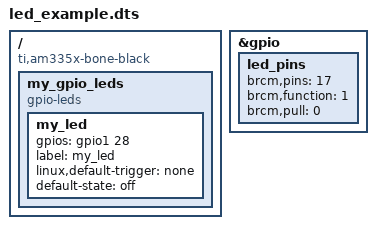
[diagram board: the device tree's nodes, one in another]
/*
 * led_example.dts - Device Tree Overlay for LED Control
 *
 * AUTO-GENERATED: This file was generated by AI. Verify before use.
 *
 * This overlay demonstrates how to add LED devices to the device tree.
 * It uses the Linux gpio-leds driver to expose LEDs via /sys/class/leds/
 *
 * Target: BeagleBone Black Rev. C (AM335x)
 * GPIO configuration uses the AM335x GPIO banks.
 *
 * Compilation:
 *   dtc -@ -I dts -O dtb -o led_example.dtbo led_example.dts
 *
 * Installation (BeagleBone Black):
 *   sudo cp led_example.dtbo /lib/firmware/
 *   # Load at runtime:
 *   echo led_example > /sys/devices/platform/bone_capemgr/slots
 *   # Or configure via uEnv.txt for boot-time loading
 *
 * Verification:
 *   ls /sys/class/leds/
 *   cat /sys/class/leds/my_led/trigger
 *   echo 1 > /sys/class/leds/my_led/brightness
 *   echo 0 > /sys/class/leds/my_led/brightness
 *
 * Hardware Connection (BeagleBone Black P9 Header):
 *   P9_12 (GPIO1_28 = GPIO 60) --> LED anode (+)
 *   P9_1 or P9_2 (GND)         --> LED cathode (-) through 330Ω resistor
 *
 * AM335x GPIO Numbering:
 *   GPIO bank 0: GPIO 0-31   (e.g., GPIO0_7 = GPIO 7)
 *   GPIO bank 1: GPIO 32-63  (e.g., GPIO1_28 = GPIO 60)
 *   GPIO bank 2: GPIO 64-95  (e.g., GPIO2_1 = GPIO 65)
 *   GPIO bank 3: GPIO 96-127 (e.g., GPIO3_19 = GPIO 115)
 */

/dts-v1/;
/plugin/;

/ {
    /*
     * Compatibility string for BeagleBone Black
     */
    compatible = "ti,am335x-bone-black", "ti,am335x-bone", "ti,am33xx";

    /*
     * Fragment 0: Add LED device to root node
     */
    fragment@0 {
        target-path = "/";
        __overlay__ {
            /*
             * GPIO LEDs container node
             * Uses the standard Linux gpio-leds driver
             */
            my_gpio_leds {
                compatible = "gpio-leds";
                
                /*
                 * LED 1: Simple status LED on GPIO1_28 (P9_12)
                 * GPIO number = (bank * 32) + offset = (1 * 32) + 28 = 60
                 */
                my_led: my_led {
                    /*
                     * GPIO specification for AM335x:
                     * <&gpioN OFFSET FLAGS>
                     * 
                     * BeagleBone Black has gpio0, gpio1, gpio2, gpio3
                     * 
                     * Flags:
                     *   GPIO_ACTIVE_HIGH = 0
                     *   GPIO_ACTIVE_LOW  = 1
                     */
                    gpios = <&gpio1 28 0>;  /* GPIO1_28 (P9_12), active high */
                    
                    /*
                     * Label appears in /sys/class/leds/<label>/
                     */
                    label = "my_led";
                    
                    /*
                     * Available triggers:
                     *   none       - Manual control only
                     *   heartbeat  - Kernel heartbeat pattern
                     *   timer      - Configurable on/off times
                     *   mmc0       - SD card activity
                     *   cpu0       - CPU activity
                     *   gpio       - Follows another GPIO
                     *   default-on - LED on by default
                     *
                     * List all: cat /sys/class/leds/my_led/trigger
                     */
                    linux,default-trigger = "none";
                    
                    /*
                     * Default state at boot:
                     *   0 = off
                     *   1 = on
                     */
                    default-state = "off";
                };
                
                /*
                 * LED 2: Heartbeat LED on GPIO1_17 (P9_23) - optional
                 * Uncomment to add second LED
                 */
                /*
                heartbeat_led: heartbeat_led {
                    gpios = <&gpio 27 0>;
                    label = "heartbeat";
                    linux,default-trigger = "heartbeat";
                    default-state = "on";
                };
                */
                
                /*
                 * LED 3: Activity LED on GPIO 22 (optional)
                 * Shows MMC/SD card activity
                 */
                /*
                activity_led: activity_led {
                    gpios = <&gpio 22 0>;
                    label = "activity";
                    linux,default-trigger = "mmc0";
                };
                */
            };
        };
    };

    /*
     * Fragment 1: Configure GPIO pin as output (optional)
     * Some platforms require explicit pinmux configuration
     */
    fragment@1 {
        target = <&gpio>;
        __overlay__ {
            /*
             * Pin configuration for LED GPIOs
             * Specific to Broadcom/Raspberry Pi pinctrl
             */
            led_pins: led_pins {
                brcm,pins = <17>;       /* GPIO numbers */
                brcm,function = <1>;    /* 1 = output */
                brcm,pull = <0>;        /* 0 = none, 1 = down, 2 = up */
            };
        };
    };

    /*
     * Parameters (Raspberry Pi specific)
     * Allows customization from config.txt:
     *   dtoverlay=led_example,gpio_pin=18
     */
    __overrides__ {
        gpio_pin = <&my_led>,"gpios:4";  /* Override GPIO number */
        /* Format: <&node>,"property:byte_offset" */
    };
};

/*
 * ===========================================================================
 * BeagleBone Black Version
 * ===========================================================================
 * Uncomment and use this version for BeagleBone Black
 *
 * /dts-v1/;
 * /plugin/;
 * 
 * / {
 *     compatible = "ti,am335x-bone-black";
 *     
 *     fragment@0 {
 *         target-path = "/";
 *         __overlay__ {
 *             bbb_leds {
 *                 compatible = "gpio-leds";
 *                 pinctrl-names = "default";
 *                 pinctrl-0 = <&bbb_led_pins>;
 *                 
 *                 bbb_led {
 *                     // GPIO1_28 = 32 + 28 = 60
 *                     gpios = <&gpio1 28 GPIO_ACTIVE_HIGH>;
 *                     label = "bbb_status";
 *                     linux,default-trigger = "heartbeat";
 *                 };
 *             };
 *         };
 *     };
 *     
 *     fragment@1 {
 *         target = <&am33xx_pinmux>;
 *         __overlay__ {
 *             bbb_led_pins: bbb_led_pins {
 *                 pinctrl-single,pins = <
 *                     AM33XX_IOPAD(0x878, PIN_OUTPUT | MUX_MODE7)  // GPIO1_28
 *                 >;
 *             };
 *         };
 *     };
 * };
 */

/*
 * ===========================================================================
 * Usage Instructions
 * ===========================================================================
 *
 * 1. Compile the overlay:
 *    dtc -@ -I dts -O dtb -o led_example.dtbo led_example.dts
 *    
 *    Note: -@ flag is needed to preserve phandle references
 *
 * 2. For Raspberry Pi:
 *    sudo cp led_example.dtbo /boot/overlays/
 *    Add to /boot/config.txt: dtoverlay=led_example
 *    sudo reboot
 *
 * 3. For BeagleBone:
 *    sudo cp led_example.dtbo /lib/firmware/
 *    Apply at runtime or via boot configuration
 *
 * 4. Test LED control:
 *    # Turn on
 *    echo 1 > /sys/class/leds/my_led/brightness
 *    
 *    # Turn off
 *    echo 0 > /sys/class/leds/my_led/brightness
 *    
 *    # Set heartbeat trigger
 *    echo heartbeat > /sys/class/leds/my_led/trigger
 *    
 *    # Set timer trigger (blinking)
 *    echo timer > /sys/class/leds/my_led/trigger
 *    echo 100 > /sys/class/leds/my_led/delay_on
 *    echo 900 > /sys/class/leds/my_led/delay_off
 *
 * 5. Verify overlay applied:
 *    ls /proc/device-tree/my_gpio_leds/
 *    cat /proc/device-tree/my_gpio_leds/my_led/label
 */
